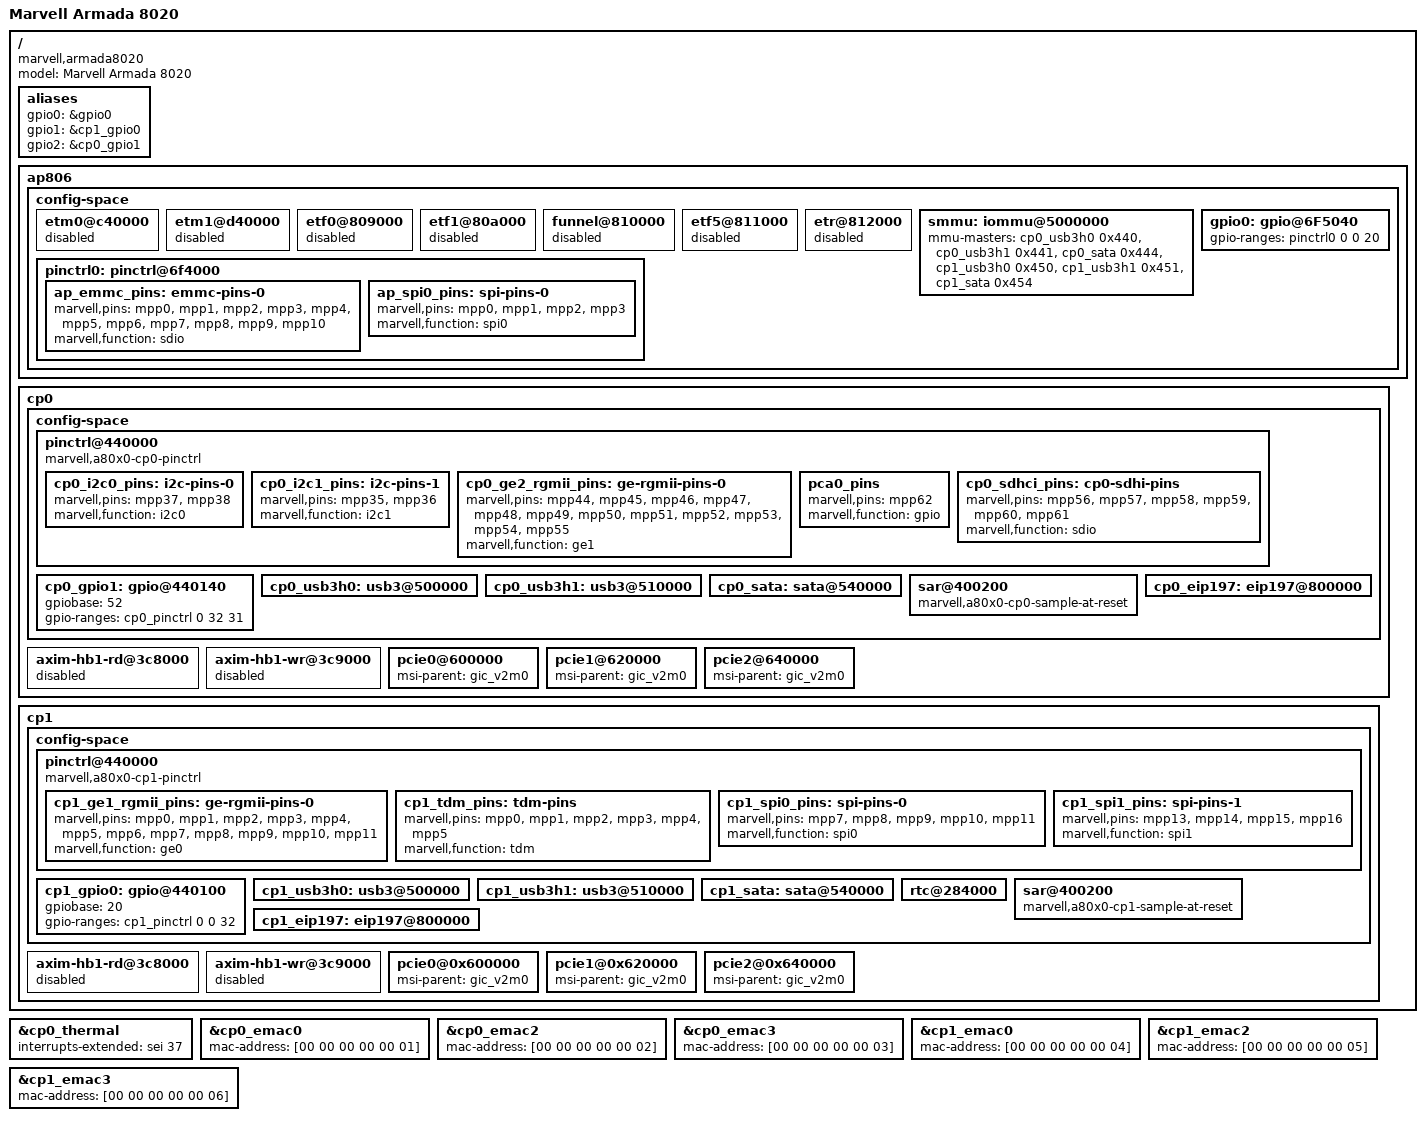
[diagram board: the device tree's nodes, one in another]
/*
 * Copyright (C) 2016 Marvell Technology Group Ltd.
 *
 * This file is dual-licensed: you can use it either under the terms
 * of the GPLv2 or the X11 license, at your option. Note that this dual
 * licensing only applies to this file, and not this project as a
 * whole.
 *
 *  a) This library is free software; you can redistribute it and/or
 *     modify it under the terms of the GNU General Public License as
 *     published by the Free Software Foundation; either version 2 of the
 *     License, or (at your option) any later version.
 *
 *     This library is distributed in the hope that it will be useful,
 *     but WITHOUT ANY WARRANTY; without even the implied warranty of
 *     MERCHANTABILITY or FITNESS FOR A PARTICULAR PURPOSE.  See the
 *     GNU General Public License for more details.
 *
 * Or, alternatively,
 *
 *  b) Permission is hereby granted, free of charge, to any person
 *     obtaining a copy of this software and associated documentation
 *     files (the "Software"), to deal in the Software without
 *     restriction, including without limitation the rights to use,
 *     copy, modify, merge, publish, distribute, sublicense, and/or
 *     sell copies of the Software, and to permit persons to whom the
 *     Software is furnished to do so, subject to the following
 *     conditions:
 *
 *     The above copyright notice and this permission notice shall be
 *     included in all copies or substantial portions of the Software.
 *
 *     THE SOFTWARE IS PROVIDED "AS IS", WITHOUT WARRANTY OF ANY KIND,
 *     EXPRESS OR IMPLIED, INCLUDING BUT NOT LIMITED TO THE WARRANTIES
 *     OF MERCHANTABILITY, FITNESS FOR A PARTICULAR PURPOSE AND
 *     NONINFRINGEMENT. IN NO EVENT SHALL THE AUTHORS OR COPYRIGHT
 *     HOLDERS BE LIABLE FOR ANY CLAIM, DAMAGES OR OTHER LIABILITY,
 *     WHETHER IN AN ACTION OF CONTRACT, TORT OR OTHERWISE, ARISING
 *     FROM, OUT OF OR IN CONNECTION WITH THE SOFTWARE OR THE USE OR
 *     OTHER DEALINGS IN THE SOFTWARE.
 */

/*
 * Device Tree file for the Armada 8020 SoC, made of an AP806 Dual and
 * two CP110.
 */

#include "armada-common.dtsi"
#include <dt-bindings/phy/phy-comphy-mvebu.h>
#include "armada-8k.dtsi"
#include "armada-ap806-dual.dtsi"

/* CP110-0 Settings */
#define CP110_NAME				cp0
#define CP110_NUM				0

#include "armada-cp110.dtsi"

#undef CP110_NAME
#undef CP110_NUM

&cp0_thermal {
	/* interrupt assignment by ICU supports single thermal sensor unit,
	* currently cp0 thermal sensor irq only is enabled.
	* To enable cp1 thermal sensor interrupt,
	* first disable cp0 thermal sensor interrupt.
	*/
	interrupts-extended = <&sei 37>;
};

&cp0_emac0 {
	mac-address = [00 00 00 00 00 01];
};

&cp0_emac2 {
	mac-address = [00 00 00 00 00 02];
};

&cp0_emac3 {
	mac-address = [00 00 00 00 00 03];
};

/* CP110-1 Settings */
#define CP110_NAME				cp1
#define CP110_NUM				1


#include "armada-cp110.dtsi"

#undef CP110_NAME
#undef CP110_NUM

&cp1_emac0 {
	mac-address = [00 00 00 00 00 04];
};

&cp1_emac2 {
	mac-address = [00 00 00 00 00 05];
};

&cp1_emac3 {
	mac-address = [00 00 00 00 00 06];
};

/ {
	model = "Marvell Armada 8020";
	compatible = "marvell,armada8020", "marvell,armada-ap806-dual",
	             "marvell,armada-ap806";
	aliases {
		gpio0 = &gpio0;
		gpio1 = &cp1_gpio0;
		gpio2 = &cp0_gpio1;
	};

	ap806 {
		config-space {
			/* Temp: disable all Coresight nodes */
			etm0@c40000 {
				status = "disabled";
			};
			etm1@d40000 {
				status = "disabled";
			};
			etf0@809000 {
				status = "disabled";
			};
			etf1@80a000 {
				status = "disabled";
			};
			funnel@810000 {
				status = "disabled";
			};
			etf5@811000 {
				status = "disabled";
			};
			etr@812000 {
				status = "disabled";
			};
			smmu: iommu@5000000 {
				mmu-masters = <&cp0_usb3h0 0x440>,
					      <&cp0_usb3h1 0x441>,
					      <&cp0_sata 0x444>,
					      <&cp1_usb3h0 0x450>,
					      <&cp1_usb3h1 0x451>,
					      <&cp1_sata 0x454>;
			};
			pinctrl0: pinctrl@6f4000 {
				ap_emmc_pins: emmc-pins-0 {
					marvell,pins = "mpp0", "mpp1", "mpp2",
					"mpp3", "mpp4", "mpp5", "mpp6", "mpp7",
					"mpp8", "mpp9", "mpp10";
					marvell,function = "sdio";
				};
				ap_spi0_pins: spi-pins-0 {
					marvell,pins = "mpp0", "mpp1", "mpp2",
					"mpp3";
					marvell,function = "spi0";
				};
			};
			gpio0: gpio@6F5040 {
				gpio-ranges = <&pinctrl0 0 0 20>;
			};
		};
	};

	cp0 {
		config-space {
			pinctrl@440000 {
				compatible = "marvell,a80x0-cp0-pinctrl";

				cp0_i2c0_pins: i2c-pins-0 {
					marvell,pins = "mpp37", "mpp38";
					marvell,function = "i2c0";
				};
				cp0_i2c1_pins: i2c-pins-1 {
					marvell,pins = "mpp35", "mpp36";
					marvell,function = "i2c1";
				};
				cp0_ge2_rgmii_pins: ge-rgmii-pins-0 {
					marvell,pins = "mpp44", "mpp45", "mpp46",
						       "mpp47", "mpp48", "mpp49",
						       "mpp50", "mpp51", "mpp52",
						       "mpp53", "mpp54", "mpp55";
					marvell,function = "ge1";
				};
				pca0_pins: pca0_pins {
					marvell,pins = "mpp62";
					marvell,function = "gpio";
				};
				cp0_sdhci_pins: cp0-sdhi-pins {
					marvell,pins = "mpp56", "mpp57", "mpp58",
						       "mpp59", "mpp60", "mpp61";
					marvell,function = "sdio";
				};
			};
			cp0_gpio1: gpio@440140 {
				gpiobase = <52>;
				gpio-ranges = <&cp0_pinctrl 0 32 31>;
			};
			cp0_usb3h0: usb3@500000 {
				#stream-id-cells = <1>;
			};
			cp0_usb3h1: usb3@510000 {
				#stream-id-cells = <1>;
			};
			cp0_sata: sata@540000 {
				#stream-id-cells = <1>;
			};
			sar@400200 {
				compatible = "marvell,a80x0-cp0-sample-at-reset";
			};
			cp0_eip197: eip197@800000 {
				status = "okay";
			};
		};
		axim-hb1-rd@3c8000 {
			status = "disabled";
		};
		axim-hb1-wr@3c9000 {
			status = "disabled";
		};
		pcie0@600000 {
			msi-parent = <&gic_v2m0>;
		};
		pcie1@620000 {
			msi-parent = <&gic_v2m0>;
		};
		pcie2@640000 {
			msi-parent = <&gic_v2m0>;
		};
	};

	cp1 {
		config-space {
			pinctrl@440000 {
				compatible = "marvell,a80x0-cp1-pinctrl";

				cp1_ge1_rgmii_pins: ge-rgmii-pins-0 {
					marvell,pins = "mpp0", "mpp1", "mpp2",
						       "mpp3", "mpp4", "mpp5",
						       "mpp6", "mpp7", "mpp8",
						       "mpp9", "mpp10", "mpp11";
					marvell,function = "ge0";
				};
				cp1_tdm_pins: tdm-pins {
					marvell,pins = "mpp0", "mpp1", "mpp2",
						       "mpp3", "mpp4", "mpp5";
					marvell,function = "tdm";
				};
				cp1_spi0_pins: spi-pins-0 {
					marvell,pins = "mpp7", "mpp8", "mpp9",
						       "mpp10", "mpp11";
					marvell,function = "spi0";
				};
				cp1_spi1_pins: spi-pins-1 {
					marvell,pins = "mpp13", "mpp14", "mpp15",
						       "mpp16";
					marvell,function = "spi1";
				};
			};
			cp1_gpio0: gpio@440100 {
				gpiobase = <20>;
				gpio-ranges = <&cp1_pinctrl 0 0 32>;
			};
			cp1_usb3h0: usb3@500000 {
				#stream-id-cells = <1>;
			};
			cp1_usb3h1: usb3@510000 {
				#stream-id-cells = <1>;
			};
			cp1_sata: sata@540000 {
				#stream-id-cells = <1>;
			};
			rtc@284000 {
				status = "okay";
			};
			sar@400200 {
				compatible = "marvell,a80x0-cp1-sample-at-reset";
			};
			cp1_eip197: eip197@800000 {
				status = "okay";
			};
		};
		axim-hb1-rd@3c8000 {
			status = "disabled";
		};
		axim-hb1-wr@3c9000 {
			status = "disabled";
		};
		pcie0@0x600000 {
			msi-parent = <&gic_v2m0>;
		};
		pcie1@0x620000 {
			msi-parent = <&gic_v2m0>;
		};
		pcie2@0x640000 {
			msi-parent = <&gic_v2m0>;
		};
	};

};
